VERSION ""

NS_ :

BS_:

BU_: Hand Robot

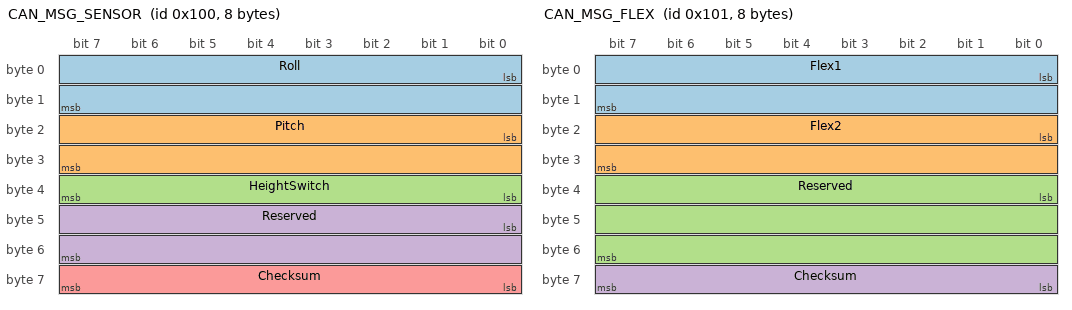
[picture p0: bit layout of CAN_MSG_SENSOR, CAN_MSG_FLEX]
BO_ 256 CAN_MSG_SENSOR: 8 Hand
 SG_ Roll : 0|16@1- (0.1,0) [-180|180] "deg" Robot
 SG_ Pitch : 16|16@1- (0.1,0) [-180|180] "deg" Robot
 SG_ HeightSwitch : 32|8@1+ (1,0) [0|2] "" Robot
 SG_ Reserved : 40|16@1+ (1,0) [0|65535] "" Robot
 SG_ Checksum : 56|8@1+ (1,0) [0|255] "" Robot

BO_ 257 CAN_MSG_FLEX: 8 Hand
 SG_ Flex1 : 0|16@1+ (1,0) [0|4095] "count" Robot
 SG_ Flex2 : 16|16@1+ (1,0) [0|4095] "count" Robot
 SG_ Reserved : 32|24@1+ (1,0) [0|16777215] "" Robot
 SG_ Checksum : 56|8@1+ (1,0) [0|255] "" Robot

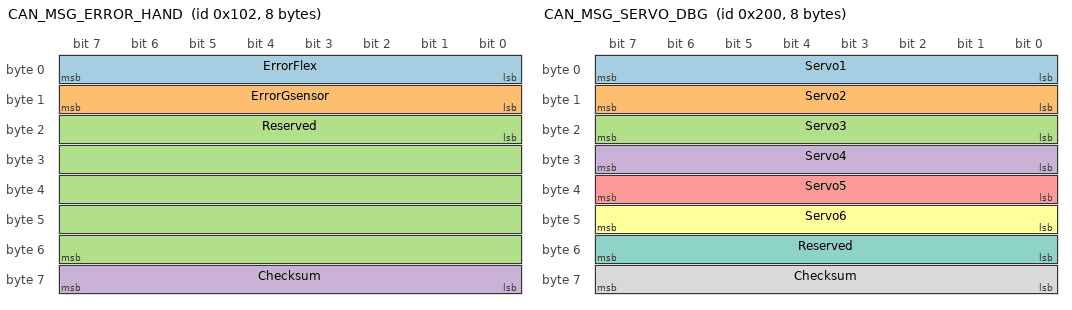
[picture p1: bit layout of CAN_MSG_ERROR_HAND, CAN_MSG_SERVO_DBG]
BO_ 258 CAN_MSG_ERROR_HAND: 8 Hand
 SG_ ErrorFlex : 0|8@1+ (1,0) [0|3] "" Robot
 SG_ ErrorGsensor : 8|8@1+ (1,0) [0|3] "" Robot
 SG_ Reserved : 16|40@1+ (1,0) [0|1099511627775] "" Robot
 SG_ Checksum : 56|8@1+ (1,0) [0|255] "" Robot

BO_ 512 CAN_MSG_SERVO_DBG: 8 Robot
 SG_ Servo1 : 0|8@1- (1,0) [-90|90] "deg" Hand
 SG_ Servo2 : 8|8@1- (1,0) [-90|90] "deg" Hand
 SG_ Servo3 : 16|8@1- (1,0) [-90|90] "deg" Hand
 SG_ Servo4 : 24|8@1- (1,0) [-90|90] "deg" Hand
 SG_ Servo5 : 32|8@1- (1,0) [-90|90] "deg" Hand
 SG_ Servo6 : 40|8@1- (1,0) [-90|90] "deg" Hand
 SG_ Reserved : 48|8@1+ (1,0) [0|255] "" Hand
 SG_ Checksum : 56|8@1+ (1,0) [0|255] "" Hand

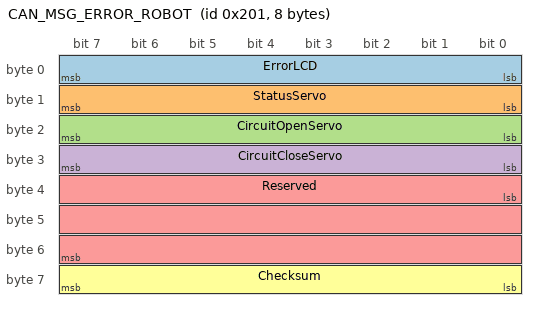
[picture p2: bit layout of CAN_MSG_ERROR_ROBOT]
BO_ 513 CAN_MSG_ERROR_ROBOT: 8 Robot
 SG_ ErrorLCD : 0|8@1+ (1,0) [0|3] "" Hand
 SG_ StatusServo : 8|8@1+ (1,0) [0|5] "" Hand
 SG_ CircuitOpenServo : 16|8@1+ (1,0) [0|1] "" Hand
 SG_ CircuitCloseServo : 24|8@1+ (1,0) [0|1] "" Hand
 SG_ Reserved : 32|24@1+ (1,0) [0|16777215] "" Hand
 SG_ Checksum : 56|8@1+ (1,0) [0|255] "" Hand

BA_DEF_ BO_ "GenMsgCycleTime" INT 0 10000;
BA_DEF_DEF_ "GenMsgCycleTime" 0;
BA_ "GenMsgCycleTime" BO_ 256 10;
BA_ "GenMsgCycleTime" BO_ 257 10;
BA_ "GenMsgCycleTime" BO_ 258 1000;
BA_ "GenMsgCycleTime" BO_ 512 100;
BA_ "GenMsgCycleTime" BO_ 513 1000;

CM_ "Wintersoldier RE_Robot FDCAN1 프로토콜. 500kbps Classic CAN, Standard ID(11bit), PCLK1=170MHz/Prescaler=20/Seg1=12/Seg2=4/SJW=3 (샘플포인트 76.5%). 소스: RE_Robot/Common/Packet.h. 2026-07-12 기준 RE_Robot/Hand/Core 소스와 대조 검증함. 작업 배경은 RE_Robot/자료/wintersoldier_can_session_summary.md 참고.";

CM_ BU_ Hand "글러브 컨트롤러 보드 (STM32G431KB, RE_Robot/Hand, H_C.ioc)";
CM_ BU_ Robot "로봇팔 보드 (STM32G431KB, RE_Robot/Robot, R_A.ioc)";

CM_ BO_ 256 "Hand의 FreeRTOS Timer10ms(Callback_10ms)가 10ms마다 값 변화와 무관하게 무조건 송신 (RE_Robot/Hand/Core/Src/main.c). Robot은 100ms 무수신을 연결 끊김으로 판단할 예정. Robot 쪽 수신 로직은 2026-07-12 기준 미구현.";
CM_ SG_ 256 Roll "ADXL345 기준, 부팅시 자세를 오프셋으로 빼서 0점 보정됨";
CM_ SG_ 256 Pitch "ADXL345 기준, 부팅시 자세를 오프셋으로 빼서 0점 보정됨";
CM_ SG_ 256 Checksum "byte0~6 XOR (Packet.h CALC_CHECKSUM 매크로)";

CM_ BO_ 257 "Hand의 FreeRTOS Timer10ms(Callback_10ms)가 10ms마다 값 변화와 무관하게 무조건 송신. Robot 쪽 수신 로직은 2026-07-12 기준 미구현.";
CM_ SG_ 257 Flex1 "ADC1 채널1 원시값 (DMA 연속변환, 스케일링 안 됨)";
CM_ SG_ 257 Flex2 "ADC1 채널2 원시값 (DMA 연속변환, 스케일링 안 됨)";
CM_ SG_ 257 Checksum "byte0~6 XOR (Packet.h CALC_CHECKSUM 매크로)";

CM_ BO_ 258 "2026-07-26 구현됨. Hand의 Timer100ms(Callback_100ms, main.c에서 1000ms로 재시작)가 1000ms마다 값 변화와 무관하게 무조건 송신. ErrorFlex/ErrorGsensor는 sensor.c의 Sensor_ReadAll()/HAL_ADC_ErrorCallback()에서 갱신, Sensor_SendStatus()가 송신.";
CM_ SG_ 258 ErrorFlex "HwStatus_t: 0=DISCONNECTED, 1=CONNECTED, 3=SENSOR_ERROR(판정 로직 미구현, 값만 예약)";
CM_ SG_ 258 ErrorGsensor "HwStatus_t: 0=DISCONNECTED, 1=CONNECTED, 3=SENSOR_ERROR(판정 로직 미구현, 값만 예약)";
CM_ SG_ 258 Checksum "byte0~6 XOR (Packet.h CALC_CHECKSUM 매크로)";

CM_ BO_ 512 "2026-07-26 구현됨. Robot의 Timer100ms(Callback_100ms)가 100ms마다 값 변화와 무관하게 무조건 송신 — 이제 Hand도 수신함(이전엔 컨트롤러로 전송 안 하는 설계였으나 변경됨). 서보 제어(ServoTask) 자체는 20ms 그대로 유지, CAN 송신 주기만 100ms.";
CM_ SG_ 512 Checksum "byte0~6 XOR (Packet.h CALC_CHECKSUM 매크로)";

CM_ BO_ 513 "2026-07-26 구현됨. Robot의 Timer1000ms(Callback_1000ms)가 1000ms마다 값 변화와 무관하게 무조건 송신. ErrorLCD는 lcd.c PCF8574_Write()의 I2C 실패시 갱신. StatusServo/CircuitOpenServo/CircuitCloseServo는 Servo_ReportFault() 훅이 채우는 자리인데 개방/단락을 실제 판정할 하드웨어(전류 감지 등)가 없어서 호출하는 곳이 아직 없음 — 한 번에 서보 1개 상태만 보고하는 포맷.";
CM_ SG_ 513 StatusServo "이상 있는 서보 인덱스 0~5 (servo.h의 SERVO_WAIST~SERVO_GRIP과 동일 값)";
CM_ SG_ 513 CircuitOpenServo "StatusServo가 가리키는 서보의 개방(단선) 여부: 0=정상, 1=개방";
CM_ SG_ 513 CircuitCloseServo "StatusServo가 가리키는 서보의 단락 여부: 0=정상, 1=단락";
CM_ SG_ 513 Checksum "byte0~6 XOR (Packet.h CALC_CHECKSUM 매크로)";

VAL_ 256 HeightSwitch 0 "HEIGHT_STOP" 1 "HEIGHT_UP" 2 "HEIGHT_DOWN" ;
VAL_ 258 ErrorFlex 0 "DISCONNECTED" 1 "CONNECTED" 3 "SENSOR_ERROR" ;
VAL_ 258 ErrorGsensor 0 "DISCONNECTED" 1 "CONNECTED" 3 "SENSOR_ERROR" ;
VAL_ 513 ErrorLCD 0 "DISCONNECTED" 1 "CONNECTED" 3 "SENSOR_ERROR" ;
